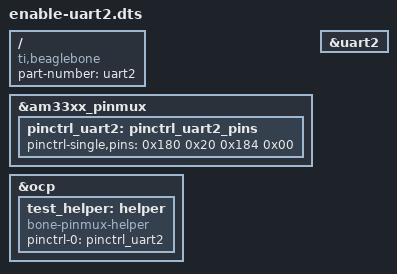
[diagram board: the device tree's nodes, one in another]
/*
 * Copyright (C) 2012 Texas Instruments Incorporated - http://www.ti.com/
 *
 * This program is free software; you can redistribute it and/or modify
 * it under the terms of the GNU General Public License version 2 as
 * published by the Free Software Foundation.
 */
/dts-v1/;
/plugin/;

/ {
    compatible = "ti,beaglebone", "ti,beaglebone-black";

    /* identification */
    part-number = "uart2";

    fragment@0 {
        target = <&am33xx_pinmux>;
        __overlay__ {
            pinctrl_uart2: pinctrl_uart2_pins {
                pinctrl-single,pins = <
						0x180 0x20  /* UART1_RXD muxRegOffset, INPUT | MODE0 */
						0x184 0x00  /* UART1_TXD muxRegOffset, OUTPUT | MODE0 */
                >;
            };
        };
    };

	fragment@1{
		target = <&uart2>;
		__overlay__ {
			status			= "okay";
		};
	};

    fragment@2 {
        target = <&ocp>;
        __overlay__ {
            test_helper: helper {
                compatible = "bone-pinmux-helper";
                pinctrl-names = "default";
                pinctrl-0 = <&pinctrl_uart2>;
                status = "okay";
            };
        };
    };
};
